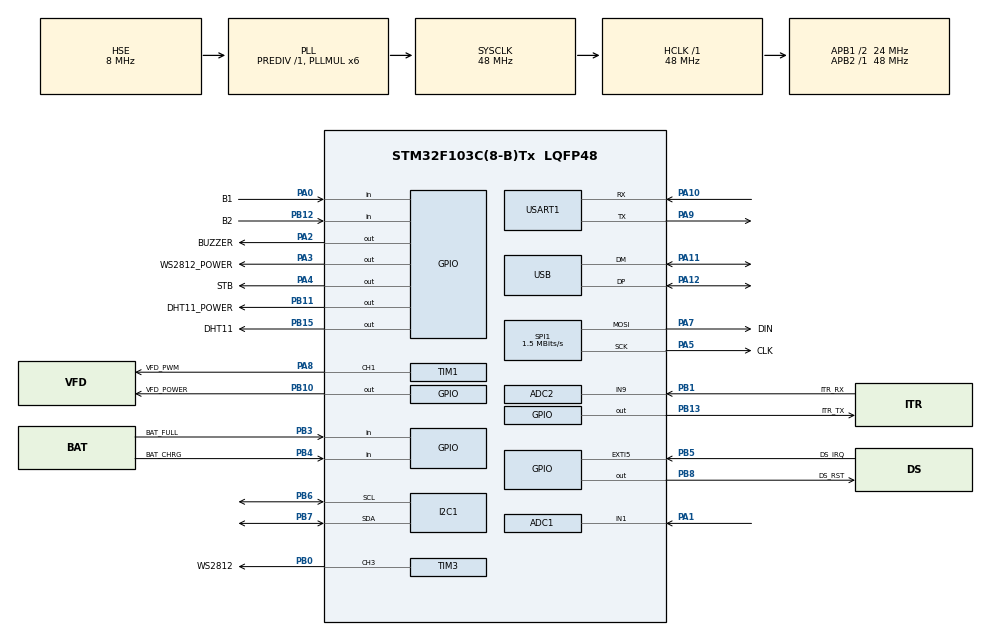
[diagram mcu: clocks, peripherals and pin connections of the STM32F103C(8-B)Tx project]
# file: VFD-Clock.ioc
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ADC1.Channel-0\#ChannelRegularConversion=ADC_CHANNEL_1
ADC1.NbrOfConversionFlag=1
ADC1.Rank-0\#ChannelRegularConversion=1
ADC1.SamplingTime-0\#ChannelRegularConversion=ADC_SAMPLETIME_55CYCLES_5
ADC1.master=1
ADC2.Channel-0\#ChannelRegularConversion=ADC_CHANNEL_9
ADC2.NbrOfConversionFlag=1
ADC2.Rank-0\#ChannelRegularConversion=1
ADC2.SamplingTime-0\#ChannelRegularConversion=ADC_SAMPLETIME_1CYCLE_5
Dma.Request0=TIM3_CH3
Dma.TIM3_CH3.0.Direction=DMA_MEMORY_TO_PERIPH
Dma.TIM3_CH3.0.Instance=DMA1_Channel2
Dma.TIM3_CH3.0.MemDataAlignment=DMA_MDATAALIGN_HALFWORD
Dma.TIM3_CH3.0.MemInc=DMA_MINC_ENABLE
Dma.TIM3_CH3.0.Mode=DMA_CIRCULAR
Dma.TIM3_CH3.0.PeriphDataAlignment=DMA_PDATAALIGN_HALFWORD
Dma.TIM3_CH3.0.PeriphInc=DMA_PINC_DISABLE
Dma.TIM3_CH3.0.Priority=DMA_PRIORITY_MEDIUM
FREERTOS.Mutexes01=vfdIconMutex,Dynamic,NULL,Available
FREERTOS.Tasks01=defaultTask,24,256,StartDefaultTask,Default,NULL,Dynamic,NULL,NULL;dht11Task,24,128,StartDHT11Task,Default,NULL,Dynamic,NULL,NULL;keyScanTask,24,128,StartKeyScanTask,Default,NULL,Dynamic,NULL,NULL;ledTask,24,512,StartLedTask,Default,NULL,Dynamic,NULL,NULL
FREERTOS.configTOTAL_HEAP_SIZE=8192
I2C1.I2C_Mode=I2C_Fast
Mcu.Family=STM32F1
Mcu.Name=STM32F103C(8-B)Tx
Mcu.Package=LQFP48
NVIC.DMA1_Channel2_IRQn=true\:5\:0\:false\:false\:true\:true\:false\:true\:true
NVIC.PriorityGroup=NVIC_PRIORITYGROUP_4
NVIC.TIM2_IRQn=true\:5\:0\:false\:false\:true\:true\:true\:true\:true
NVIC.TIM3_IRQn=true\:5\:0\:false\:false\:true\:true\:true\:true\:true
NVIC.TIM4_IRQn=true\:15\:0\:false\:false\:true\:false\:false\:true\:true
NVIC.TimeBase=TIM4_IRQn
NVIC.TimeBaseIP=TIM4
NVIC.USART1_IRQn=true\:5\:0\:false\:false\:true\:true\:true\:true\:true
NVIC.USB_LP_CAN1_RX0_IRQn=true\:5\:0\:false\:false\:true\:true\:false\:true\:true
PA0-WKUP.GPIO_Label=B1
PA0-WKUP.GPIO_PuPd=GPIO_PULLUP
PA0-WKUP.Signal=GPIO_Input
PA1.Signal=ADCx_IN1
PA10.Mode=Asynchronous
PA10.Signal=USART1_RX
PA11.Mode=Device
PA11.Signal=USB_DM
PA12.Mode=Device
PA12.Signal=USB_DP
PA13.Mode=Serial_Wire
PA13.Signal=SYS_JTMS-SWDIO
PA14.Mode=Serial_Wire
PA14.Signal=SYS_JTCK-SWCLK
PA2.GPIO_Label=BUZZER
PA2.Signal=GPIO_Output
PA3.GPIO_Label=WS2812_POWER
PA3.GPIO_ModeDefaultOutputPP=GPIO_MODE_OUTPUT_OD
PA3.GPIO_PuPd=GPIO_PULLUP
PA3.PinState=GPIO_PIN_SET
PA3.Signal=GPIO_Output
PA4.GPIO_Label=STB
PA4.GPIO_ModeDefaultOutputPP=GPIO_MODE_OUTPUT_PP
PA4.GPIO_PuPd=GPIO_PULLUP
PA4.GPIO_Speed=GPIO_SPEED_FREQ_HIGH
PA4.Signal=GPIO_Output
PA5.GPIO_Label=CLK
PA5.Mode=TX_Only_Simplex_Unidirect_Master
PA5.Signal=SPI1_SCK
PA7.GPIO_Label=DIN
PA7.Mode=TX_Only_Simplex_Unidirect_Master
PA7.Signal=SPI1_MOSI
PA8.GPIO_Label=VFD_PWM
PA8.Signal=S_TIM1_CH1
PA9.Mode=Asynchronous
PA9.Signal=USART1_TX
PB0.GPIO_Label=WS2812
PB0.Signal=S_TIM3_CH3
PB1.GPIO_Label=ITR_RX
PB1.Signal=ADCx_IN9
PB10.GPIO_Label=VFD_POWER
PB10.GPIO_ModeDefaultOutputPP=GPIO_MODE_OUTPUT_OD
PB10.GPIO_PuPd=GPIO_PULLUP
PB10.PinState=GPIO_PIN_SET
PB10.Signal=GPIO_Output
PB11.GPIO_Label=DHT11_POWER
PB11.GPIO_ModeDefaultOutputPP=GPIO_MODE_OUTPUT_OD
PB11.GPIO_PuPd=GPIO_PULLUP
PB11.PinState=GPIO_PIN_SET
PB11.Signal=GPIO_Output
PB12.GPIO_Label=B2
PB12.GPIO_PuPd=GPIO_PULLUP
PB12.Signal=GPIO_Input
PB13.GPIO_Label=ITR_TX
PB13.GPIO_ModeDefaultOutputPP=GPIO_MODE_OUTPUT_OD
PB13.GPIO_PuPd=GPIO_NOPULL
PB13.PinState=GPIO_PIN_SET
PB13.Signal=GPIO_Output
PB15.GPIO_Label=DHT11
PB15.GPIO_ModeDefaultOutputPP=GPIO_MODE_OUTPUT_OD
PB15.GPIO_PuPd=GPIO_PULLUP
PB15.GPIO_Speed=GPIO_SPEED_FREQ_HIGH
PB15.Signal=GPIO_Output
PB3.GPIO_Label=BAT_FULL
PB3.GPIO_PuPd=GPIO_PULLUP
PB3.Signal=GPIO_Input
PB4.GPIO_Label=BAT_CHRG
PB4.GPIO_PuPd=GPIO_PULLUP
PB4.Signal=GPIO_Input
PB5.GPIO_Label=DS_IRQ
PB5.Signal=GPXTI5
PB6.Mode=I2C
PB6.Signal=I2C1_SCL
PB7.Mode=I2C
PB7.Signal=I2C1_SDA
PB8.GPIO_Label=DS_RST
PB8.Signal=GPIO_Output
PC14-OSC32_IN.Mode=LSE-External-Clock-Source
PC14-OSC32_IN.Signal=RCC_OSC32_IN
PC15-OSC32_OUT.Mode=LSE-External-Clock-Source
PC15-OSC32_OUT.Signal=RCC_OSC32_OUT
PD0-OSC_IN.Mode=HSE-External-Oscillator
PD0-OSC_IN.Signal=RCC_OSC_IN
PD1-OSC_OUT.Mode=HSE-External-Oscillator
PD1-OSC_OUT.Signal=RCC_OSC_OUT
ProjectManager.HeapSize=0x200
ProjectManager.StackSize=0x400
ProjectManager.TargetToolchain=MDK-ARM V5.32
RCC.ADCPresc=RCC_ADCPCLK2_DIV4
RCC.AHBFreq_Value=48000000
RCC.APB1CLKDivider=RCC_HCLK_DIV2
RCC.APB1Freq_Value=24000000
RCC.APB1TimFreq_Value=48000000
RCC.APB2Freq_Value=48000000
RCC.APB2TimFreq_Value=48000000
RCC.HCLKFreq_Value=48000000
RCC.PLLMUL=RCC_PLL_MUL6
RCC.PLLSourceVirtual=RCC_PLLSOURCE_HSE
RCC.SYSCLKFreq_VALUE=48000000
RCC.SYSCLKSource=RCC_SYSCLKSOURCE_PLLCLK
RCC.USBFreq_Value=48000000
SH.ADCx_IN1.0=ADC1_IN1,IN1
SH.ADCx_IN9.0=ADC2_IN9,IN9
SH.S_TIM1_CH1.0=TIM1_CH1,PWM Generation1 CH1
SH.S_TIM3_CH3.0=TIM3_CH3,PWM Generation3 CH3
SPI1.BaudRatePrescaler=SPI_BAUDRATEPRESCALER_32
SPI1.CalculateBaudRate=1.5 MBits/s
SPI1.Direction=SPI_DIRECTION_2LINES
SPI1.FirstBit=SPI_FIRSTBIT_LSB
SPI1.Mode=SPI_MODE_MASTER
SPI1.VirtualType=VM_MASTER
TIM1.AutoReloadPreload=TIM_AUTORELOAD_PRELOAD_ENABLE
TIM1.Channel-PWM\ Generation1\ CH1=TIM_CHANNEL_1
TIM1.OCFastMode_PWM-PWM\ Generation1\ CH1=TIM_OCFAST_ENABLE
TIM1.Period=100-1
TIM1.Prescaler=6-1
TIM1.Pulse-PWM\ Generation1\ CH1=5
TIM2.AutoReloadPreload=TIM_AUTORELOAD_PRELOAD_ENABLE
TIM2.Period=65535
TIM2.Prescaler=48-1
TIM3.Channel-PWM\ Generation3\ CH3=TIM_CHANNEL_3
TIM3.Period=60-1
TIM3.Prescaler=0
USART1.VirtualMode=VM_ASYNC
USB_DEVICE.CLASS_NAME_FS=CDC
USB_DEVICE.VirtualMode=Cdc
USB_DEVICE.VirtualModeFS=Cdc_FS
VP_FREERTOS_VS_CMSIS_V2.Mode=CMSIS_V2
VP_SYS_VS_tim4.Mode=TIM4
VP_TIM2_VS_ClockSourceINT.Mode=Internal
VP_USB_DEVICE_VS_USB_DEVICE_CDC_FS.Mode=CDC_FS
board=custom

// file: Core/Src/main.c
/* USER CODE BEGIN Header */
/**
  ******************************************************************************
  * @file           : main.c
  * @brief          : Main program body
  ******************************************************************************
  * @attention
  *
  * Copyright (c) 2024 STMicroelectronics.
  * All rights reserved.
  *
  * This software is licensed under terms that can be found in the LICENSE file
  * in the root directory of this software component.
  * If no LICENSE file comes with this software, it is provided AS-IS.
  *
  ******************************************************************************
  */
/* USER CODE END Header */
#include "main.h"
#include "cmsis_os.h"
#include "adc.h"
#include "dma.h"
#include "i2c.h"
#include "spi.h"
#include "tim.h"
#include "usart.h"
#include "usb_device.h"
#include "gpio.h"

void SystemClock_Config(void);
void MX_FREERTOS_Init(void);

int main(void)
{

  /* MCU Configuration--------------------------------------------------------*/

  /* Reset of all peripherals, Initializes the Flash interface and the Systick. */
  HAL_Init();

  /* Configure the system clock */
  SystemClock_Config();

  /* Initialize all configured peripherals */
  MX_GPIO_Init();
  MX_DMA_Init();
  MX_ADC1_Init();
  MX_TIM3_Init();
  MX_ADC2_Init();
  MX_I2C1_Init();
  MX_TIM1_Init();
  MX_USART1_UART_Init();
  MX_SPI1_Init();
  MX_TIM2_Init();

  /* Init scheduler */
  osKernelInitialize();

  /* Call init function for freertos objects (in cmsis_os2.c) */
  MX_FREERTOS_Init();

  /* Start scheduler */
  osKernelStart();

  /* We should never get here as control is now taken by the scheduler */

  /* Infinite loop */
  while (1)
  {

  }
}

void SystemClock_Config(void)
{
  RCC_OscInitTypeDef RCC_OscInitStruct = {0};
  RCC_ClkInitTypeDef RCC_ClkInitStruct = {0};
  RCC_PeriphCLKInitTypeDef PeriphClkInit = {0};

  /** Initializes the RCC Oscillators according to the specified parameters
  * in the RCC_OscInitTypeDef structure.
  */
  RCC_OscInitStruct.OscillatorType = RCC_OSCILLATORTYPE_HSE;
  RCC_OscInitStruct.HSEState = RCC_HSE_ON;
  RCC_OscInitStruct.HSEPredivValue = RCC_HSE_PREDIV_DIV1;
  RCC_OscInitStruct.HSIState = RCC_HSI_ON;
  RCC_OscInitStruct.PLL.PLLState = RCC_PLL_ON;
  RCC_OscInitStruct.PLL.PLLSource = RCC_PLLSOURCE_HSE;
  RCC_OscInitStruct.PLL.PLLMUL = RCC_PLL_MUL6;
  if (HAL_RCC_OscConfig(&RCC_OscInitStruct) != HAL_OK)
  {
    Error_Handler();
  }

  /** Initializes the CPU, AHB and APB buses clocks
  */
  RCC_ClkInitStruct.ClockType = RCC_CLOCKTYPE_HCLK|RCC_CLOCKTYPE_SYSCLK
                              |RCC_CLOCKTYPE_PCLK1|RCC_CLOCKTYPE_PCLK2;
  RCC_ClkInitStruct.SYSCLKSource = RCC_SYSCLKSOURCE_PLLCLK;
  RCC_ClkInitStruct.AHBCLKDivider = RCC_SYSCLK_DIV1;
  RCC_ClkInitStruct.APB1CLKDivider = RCC_HCLK_DIV2;
  RCC_ClkInitStruct.APB2CLKDivider = RCC_HCLK_DIV1;

  if (HAL_RCC_ClockConfig(&RCC_ClkInitStruct, FLASH_LATENCY_1) != HAL_OK)
  {
    Error_Handler();
  }
  PeriphClkInit.PeriphClockSelection = RCC_PERIPHCLK_ADC|RCC_PERIPHCLK_USB;
  PeriphClkInit.AdcClockSelection = RCC_ADCPCLK2_DIV4;
  PeriphClkInit.UsbClockSelection = RCC_USBCLKSOURCE_PLL;
  if (HAL_RCCEx_PeriphCLKConfig(&PeriphClkInit) != HAL_OK)
  {
    Error_Handler();
  }
}

void HAL_TIM_PeriodElapsedCallback(TIM_HandleTypeDef *htim)
{
  if (htim->Instance == TIM4) {
    HAL_IncTick();
  }
}

void Error_Handler(void)
{
  __disable_irq();
  while (1)
  {
  }
}

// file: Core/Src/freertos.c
/* USER CODE BEGIN Header */
/**
  ******************************************************************************
  * File Name          : freertos.c
  * Description        : Code for freertos applications
  ******************************************************************************
  * @attention
  *
  * Copyright (c) 2024 STMicroelectronics.
  * All rights reserved.
  *
  * This software is licensed under terms that can be found in the LICENSE file
  * in the root directory of this software component.
  * If no LICENSE file comes with this software, it is provided AS-IS.
  *
  ******************************************************************************
  */
/* USER CODE END Header */

#include "FreeRTOS.h"
#include "task.h"
#include "main.h"
#include "cmsis_os.h"

/* USER CODE BEGIN Includes */
#include "main_app.h"
#include "temp_humidity_task.h"
#include "key_scan_task.h"
#include "led_task.h"
/* USER CODE END Includes */

/* Definitions for defaultTask */
osThreadId_t defaultTaskHandle;
const osThreadAttr_t defaultTask_attributes = {
  .name = "defaultTask",
  .stack_size = 256 * 4,
  .priority = (osPriority_t) osPriorityNormal,
};
/* Definitions for dht11Task */
osThreadId_t dht11TaskHandle;
const osThreadAttr_t dht11Task_attributes = {
  .name = "dht11Task",
  .stack_size = 128 * 4,
  .priority = (osPriority_t) osPriorityNormal,
};
/* Definitions for keyScanTask */
osThreadId_t keyScanTaskHandle;
const osThreadAttr_t keyScanTask_attributes = {
  .name = "keyScanTask",
  .stack_size = 128 * 4,
  .priority = (osPriority_t) osPriorityNormal,
};
/* Definitions for ledTask */
osThreadId_t ledTaskHandle;
const osThreadAttr_t ledTask_attributes = {
  .name = "ledTask",
  .stack_size = 512 * 4,
  .priority = (osPriority_t) osPriorityNormal,
};
/* Definitions for vfdIconMutex */
osMutexId_t vfdIconMutexHandle;
const osMutexAttr_t vfdIconMutex_attributes = {
  .name = "vfdIconMutex"
};

void StartDefaultTask(void *argument);
void StartDHT11Task(void *argument);
void StartKeyScanTask(void *argument);
void StartLedTask(void *argument);

extern void MX_USB_DEVICE_Init(void);
void MX_FREERTOS_Init(void); /* (MISRA C 2004 rule 8.1) */

void MX_FREERTOS_Init(void) {
  /* USER CODE BEGIN Init */
  periph_init();
  /* USER CODE END Init */
  /* Create the mutex(es) */
  /* creation of vfdIconMutex */
  vfdIconMutexHandle = osMutexNew(&vfdIconMutex_attributes);

  /* Create the thread(s) */
  /* creation of defaultTask */
  defaultTaskHandle = osThreadNew(StartDefaultTask, NULL, &defaultTask_attributes);

  /* creation of dht11Task */
  dht11TaskHandle = osThreadNew(StartDHT11Task, NULL, &dht11Task_attributes);

  /* creation of keyScanTask */
  keyScanTaskHandle = osThreadNew(StartKeyScanTask, NULL, &keyScanTask_attributes);

  /* creation of ledTask */
  ledTaskHandle = osThreadNew(StartLedTask, NULL, &ledTask_attributes);

}

void StartDefaultTask(void *argument)
{
  /* init code for USB_DEVICE */
  MX_USB_DEVICE_Init();
  /* USER CODE BEGIN StartDefaultTask */
  main_app();
  /* USER CODE END StartDefaultTask */
}

void StartDHT11Task(void *argument)
{
  /* USER CODE BEGIN StartDHT11Task */
  temp_humidity_task();
  /* USER CODE END StartDHT11Task */
}

void StartKeyScanTask(void *argument)
{
  /* USER CODE BEGIN StartKeyScanTask */
  key_scan_task();
  /* USER CODE END StartKeyScanTask */
}

void StartLedTask(void *argument)
{
  /* USER CODE BEGIN StartLedTask */
  led_task();
  /* USER CODE END StartLedTask */
}
